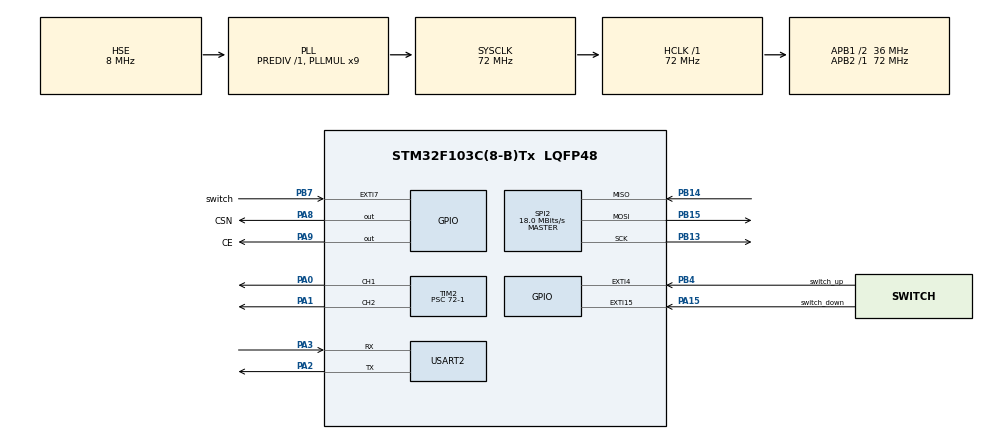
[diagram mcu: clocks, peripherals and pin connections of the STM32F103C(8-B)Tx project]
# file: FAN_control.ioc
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Mcu.Family=STM32F1
Mcu.Name=STM32F103C(8-B)Tx
Mcu.Package=LQFP48
NVIC.EXTI15_10_IRQn=true\:8\:0\:true\:false\:true\:true\:true\:true
NVIC.EXTI4_IRQn=true\:8\:0\:true\:false\:true\:true\:true\:true
NVIC.EXTI9_5_IRQn=true\:8\:0\:true\:false\:true\:true\:true\:true
NVIC.PriorityGroup=NVIC_PRIORITYGROUP_4
NVIC.TIM3_IRQn=true\:0\:0\:false\:false\:true\:true\:true\:true
PA0-WKUP.Signal=S_TIM2_CH1_ETR
PA1.Signal=S_TIM2_CH2
PA13.Mode=Serial_Wire
PA13.Signal=SYS_JTMS-SWDIO
PA14.Mode=Serial_Wire
PA14.Signal=SYS_JTCK-SWCLK
PA15.GPIO_Label=switch_down
PA15.GPIO_ModeDefaultEXTI=GPIO_MODE_IT_FALLING
PA15.GPIO_PuPd=GPIO_PULLUP
PA15.Signal=GPXTI15
PA2.Mode=Asynchronous
PA2.Signal=USART2_TX
PA3.Mode=Asynchronous
PA3.Signal=USART2_RX
PA8.GPIO_Label=CSN
PA8.Signal=GPIO_Output
PA9.GPIO_Label=CE
PA9.Signal=GPIO_Output
PB13.Mode=Full_Duplex_Master
PB13.Signal=SPI2_SCK
PB14.Mode=Full_Duplex_Master
PB14.Signal=SPI2_MISO
PB15.Mode=Full_Duplex_Master
PB15.Signal=SPI2_MOSI
PB4.GPIO_Label=switch_up
PB4.GPIO_ModeDefaultEXTI=GPIO_MODE_IT_FALLING
PB4.GPIO_PuPd=GPIO_PULLUP
PB4.Signal=GPXTI4
PB7.GPIO_Label=switch
PB7.GPIO_ModeDefaultEXTI=GPIO_MODE_IT_FALLING
PB7.GPIO_PuPd=GPIO_PULLUP
PB7.Signal=GPXTI7
PD0-OSC_IN.Mode=HSE-External-Oscillator
PD0-OSC_IN.Signal=RCC_OSC_IN
PD1-OSC_OUT.Mode=HSE-External-Oscillator
PD1-OSC_OUT.Signal=RCC_OSC_OUT
ProjectManager.HeapSize=0x200
ProjectManager.StackSize=0x400
ProjectManager.TargetToolchain=MDK-ARM V5.32
RCC.AHBFreq_Value=72000000
RCC.APB1CLKDivider=RCC_HCLK_DIV2
RCC.APB1Freq_Value=36000000
RCC.APB1TimFreq_Value=72000000
RCC.APB2Freq_Value=72000000
RCC.APB2TimFreq_Value=72000000
RCC.HCLKFreq_Value=72000000
RCC.PLLMUL=RCC_PLL_MUL9
RCC.PLLSourceVirtual=RCC_PLLSOURCE_HSE
RCC.SYSCLKFreq_VALUE=72000000
RCC.SYSCLKSource=RCC_SYSCLKSOURCE_PLLCLK
RCC.USBFreq_Value=72000000
SH.S_TIM2_CH1_ETR.0=TIM2_CH1,PWM Generation1 CH1
SH.S_TIM2_CH2.0=TIM2_CH2,PWM Generation2 CH2
SPI2.CalculateBaudRate=18.0 MBits/s
SPI2.Direction=SPI_DIRECTION_2LINES
SPI2.Mode=SPI_MODE_MASTER
SPI2.VirtualType=VM_MASTER
TIM2.Channel-PWM\ Generation1\ CH1=TIM_CHANNEL_1
TIM2.Channel-PWM\ Generation2\ CH2=TIM_CHANNEL_2
TIM2.Period=100-1
TIM2.Prescaler=72-1
TIM3.AutoReloadPreload=TIM_AUTORELOAD_PRELOAD_ENABLE
TIM3.Period=3999
TIM3.Prescaler=72-1
USART2.VirtualMode=VM_ASYNC
VP_TIM2_VS_ClockSourceINT.Mode=Internal
VP_TIM3_VS_ClockSourceINT.Mode=Internal
board=custom

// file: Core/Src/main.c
/* USER CODE BEGIN Header */
/**
  ******************************************************************************
  * @file           : main.c
  * @brief          : Main program body
  ******************************************************************************
  * @attention
  *
  * Copyright (c) 2025 STMicroelectronics.
  * All rights reserved.
  *
  * This software is licensed under terms that can be found in the LICENSE file
  * in the root directory of this software component.
  * If no LICENSE file comes with this software, it is provided AS-IS.
  *
  ******************************************************************************
  */
/* USER CODE END Header */
#include "main.h"
#include "spi.h"
#include "tim.h"
#include "usart.h"
#include "gpio.h"

/* USER CODE BEGIN Includes */
#include "drv8833.h"
#include "FAN.h"
/* USER CODE END Includes */

void SystemClock_Config(void);

/* USER CODE BEGIN 0 */
void HAL_TIM_PeriodElapsedCallback(TIM_HandleTypeDef *htim) {
  if (htim->Instance == TIM3) { // 确认是TIM3触发
    // 此处写4ms中断执行的代码

  }
}
/* USER CODE END 0 */

int main(void)
{

  /* MCU Configuration--------------------------------------------------------*/

  /* Reset of all peripherals, Initializes the Flash interface and the Systick. */
  HAL_Init();

  /* Configure the system clock */
  SystemClock_Config();

  /* Initialize all configured peripherals */
  MX_GPIO_Init();
  MX_USART2_UART_Init();
  MX_TIM2_Init();
  MX_SPI2_Init();
  MX_TIM3_Init();
  /* USER CODE BEGIN 2 */
//	HAL_TIM_Base_Start_IT(&htim3);
  Fan_Init();

  /* USER CODE END 2 */

  /* Infinite loop */
  /* USER CODE BEGIN WHILE */
  while (1)
  {
     FAN_handle();
    /* USER CODE END WHILE */

    /* USER CODE BEGIN 3 */
    // DRV8833_Forward(100);
  }
  /* USER CODE END 3 */
}

void SystemClock_Config(void)
{
  RCC_OscInitTypeDef RCC_OscInitStruct = {0};
  RCC_ClkInitTypeDef RCC_ClkInitStruct = {0};

  /** Initializes the RCC Oscillators according to the specified parameters
  * in the RCC_OscInitTypeDef structure.
  */
  RCC_OscInitStruct.OscillatorType = RCC_OSCILLATORTYPE_HSE;
  RCC_OscInitStruct.HSEState = RCC_HSE_ON;
  RCC_OscInitStruct.HSEPredivValue = RCC_HSE_PREDIV_DIV1;
  RCC_OscInitStruct.HSIState = RCC_HSI_ON;
  RCC_OscInitStruct.PLL.PLLState = RCC_PLL_ON;
  RCC_OscInitStruct.PLL.PLLSource = RCC_PLLSOURCE_HSE;
  RCC_OscInitStruct.PLL.PLLMUL = RCC_PLL_MUL9;
  if (HAL_RCC_OscConfig(&RCC_OscInitStruct) != HAL_OK)
  {
    Error_Handler();
  }

  /** Initializes the CPU, AHB and APB buses clocks
  */
  RCC_ClkInitStruct.ClockType = RCC_CLOCKTYPE_HCLK|RCC_CLOCKTYPE_SYSCLK
                              |RCC_CLOCKTYPE_PCLK1|RCC_CLOCKTYPE_PCLK2;
  RCC_ClkInitStruct.SYSCLKSource = RCC_SYSCLKSOURCE_PLLCLK;
  RCC_ClkInitStruct.AHBCLKDivider = RCC_SYSCLK_DIV1;
  RCC_ClkInitStruct.APB1CLKDivider = RCC_HCLK_DIV2;
  RCC_ClkInitStruct.APB2CLKDivider = RCC_HCLK_DIV1;

  if (HAL_RCC_ClockConfig(&RCC_ClkInitStruct, FLASH_LATENCY_2) != HAL_OK)
  {
    Error_Handler();
  }
}

void Error_Handler(void)
{
  __disable_irq();
  while (1)
  {
  }
}
